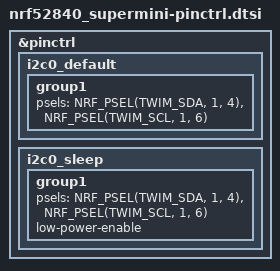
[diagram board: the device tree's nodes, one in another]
/*
 * Pin control for the SuperMini nRF52840.
 *
 * Copyright (c) 2026
 * SPDX-License-Identifier: Apache-2.0
 *
 * The SuperMini silkscreens port numbers directly: "104" is P1.04 and "106"
 * is P1.06. I2C0 is wired there, which keeps the sensor on pins that are
 * actually broken out and leaves the nice!nano defaults (P0.17 / P0.20) free.
 */

&pinctrl {
	i2c0_default: i2c0_default {
		group1 {
			psels = <NRF_PSEL(TWIM_SDA, 1, 4)>,
				<NRF_PSEL(TWIM_SCL, 1, 6)>;
		};
	};

	i2c0_sleep: i2c0_sleep {
		group1 {
			psels = <NRF_PSEL(TWIM_SDA, 1, 4)>,
				<NRF_PSEL(TWIM_SCL, 1, 6)>;
			low-power-enable;
		};
	};
};
